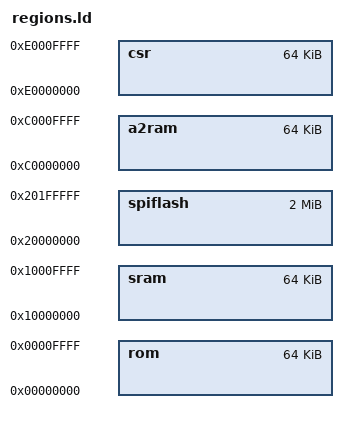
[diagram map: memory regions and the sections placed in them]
MEMORY {
	csr : ORIGIN = 0xe0000000, LENGTH = 0x00010000
	sram : ORIGIN = 0x10000000, LENGTH = 0x00010000
	a2ram : ORIGIN = 0xc0000000, LENGTH = 0x00010000
	rom : ORIGIN = 0x00000000, LENGTH = 0x00010000
	spiflash : ORIGIN = 0x20000000, LENGTH = 0x00200000
}
